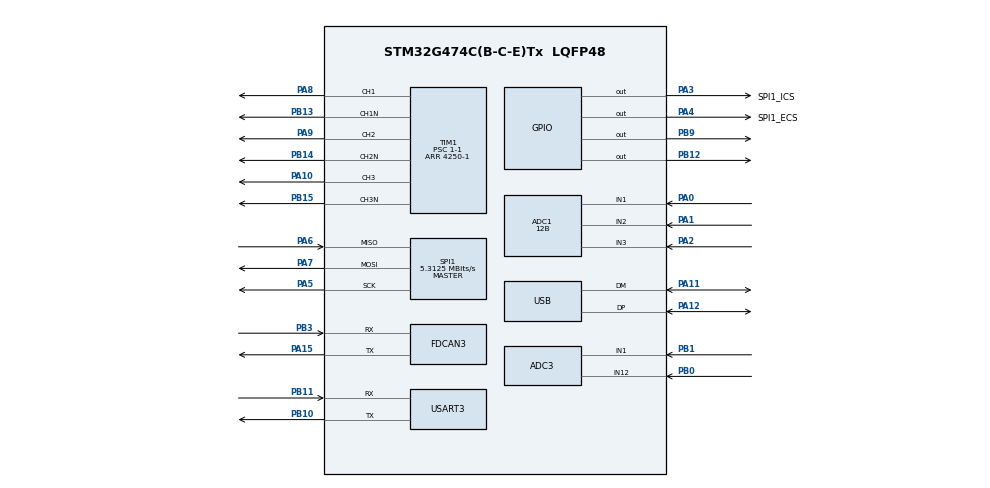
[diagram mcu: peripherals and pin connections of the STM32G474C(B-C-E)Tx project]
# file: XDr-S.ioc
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ADC1.Channel-0\#ChannelRegularConversion=ADC_CHANNEL_1
ADC1.Channel-1\#ChannelRegularConversion=ADC_CHANNEL_2
ADC1.Channel-2\#ChannelRegularConversion=ADC_CHANNEL_3
ADC1.DMAContinuousRequests=ENABLE
ADC1.ExternalTrigConv=ADC_EXTERNALTRIG_T1_TRGO
ADC1.ExternalTrigConvEdge=ADC_EXTERNALTRIGCONVEDGE_FALLING
ADC1.NbrOfConversion=3
ADC1.NbrOfConversionFlag=1
ADC1.OffsetNumber-0\#ChannelRegularConversion=ADC_OFFSET_NONE
ADC1.OffsetNumber-1\#ChannelRegularConversion=ADC_OFFSET_NONE
ADC1.OffsetNumber-2\#ChannelRegularConversion=ADC_OFFSET_NONE
ADC1.OversamplingMode=ENABLE
ADC1.Rank-0\#ChannelRegularConversion=1
ADC1.Rank-1\#ChannelRegularConversion=2
ADC1.Rank-2\#ChannelRegularConversion=3
ADC1.Ratio=ADC_OVERSAMPLING_RATIO_16
ADC1.Resolution=ADC_RESOLUTION_12B
ADC1.RightBitShift=ADC_RIGHTBITSHIFT_4
ADC1.SamplingTime-0\#ChannelRegularConversion=ADC_SAMPLETIME_2CYCLES_5
ADC1.SamplingTime-1\#ChannelRegularConversion=ADC_SAMPLETIME_2CYCLES_5
ADC1.SamplingTime-2\#ChannelRegularConversion=ADC_SAMPLETIME_2CYCLES_5
ADC1.master=1
ADC3.Channel-3\#ChannelRegularConversion=ADC_CHANNEL_12
ADC3.NbrOfConversionFlag=1
ADC3.OffsetNumber-3\#ChannelRegularConversion=ADC_OFFSET_NONE
ADC3.Rank-3\#ChannelRegularConversion=1
ADC3.SamplingTime-3\#ChannelRegularConversion=ADC_SAMPLETIME_2CYCLES_5
ADC3.master=1
Dma.ADC1.0.Direction=DMA_PERIPH_TO_MEMORY
Dma.ADC1.0.EventEnable=DISABLE
Dma.ADC1.0.Instance=DMA1_Channel1
Dma.ADC1.0.MemDataAlignment=DMA_MDATAALIGN_HALFWORD
Dma.ADC1.0.MemInc=DMA_MINC_ENABLE
Dma.ADC1.0.Mode=DMA_NORMAL
Dma.ADC1.0.PeriphDataAlignment=DMA_PDATAALIGN_HALFWORD
Dma.ADC1.0.PeriphInc=DMA_PINC_DISABLE
Dma.ADC1.0.Polarity=HAL_DMAMUX_REQ_GEN_RISING
Dma.ADC1.0.Priority=DMA_PRIORITY_HIGH
Dma.ADC1.0.RequestNumber=1
Dma.ADC1.0.SignalID=NONE
Dma.ADC1.0.SyncEnable=DISABLE
Dma.ADC1.0.SyncPolarity=HAL_DMAMUX_SYNC_NO_EVENT
Dma.ADC1.0.SyncRequestNumber=1
Dma.ADC1.0.SyncSignalID=NONE
Dma.Request0=ADC1
FDCAN3.AutoRetransmission=ENABLE
FDCAN3.CalculateBaudRateNominal=999999
FDCAN3.CalculateTimeBitNominal=1000
FDCAN3.CalculateTimeQuantumNominal=58.82352941176471
FDCAN3.DataSyncJumpWidth=3
FDCAN3.NominalPrescaler=10
FDCAN3.NominalTimeSeg1=12
FDCAN3.NominalTimeSeg2=4
FDCAN3.StdFiltersNbr=1
Mcu.Family=STM32G4
Mcu.Name=STM32G474C(B-C-E)Tx
Mcu.Package=LQFP48
NVIC.DMA1_Channel1_IRQn=true\:0\:1\:true\:false\:true\:false\:true\:true
NVIC.FDCAN3_IT0_IRQn=true\:0\:0\:false\:false\:true\:true\:true\:true
NVIC.PriorityGroup=NVIC_PRIORITYGROUP_2
NVIC.TIM1_UP_TIM16_IRQn=true\:0\:0\:false\:false\:true\:true\:true\:true
NVIC.USB_HP_IRQn=true\:0\:0\:false\:false\:true\:true\:true\:true
PA0.Mode=IN1-Single-Ended
PA0.Signal=ADC1_IN1
PA1.Mode=IN2-Single-Ended
PA1.Signal=ADC1_IN2
PA10.Signal=S_TIM1_CH3
PA11.Mode=Device
PA11.Signal=USB_DM
PA12.Mode=Device
PA12.Signal=USB_DP
PA13.Mode=Serial_Wire
PA13.Signal=SYS_JTMS-SWDIO
PA14.Mode=Serial_Wire
PA14.Signal=SYS_JTCK-SWCLK
PA15.Mode=FDCAN_Activate
PA15.Signal=FDCAN3_TX
PA2.Mode=IN3-Single-Ended
PA2.Signal=ADC1_IN3
PA3.GPIO_Label=SPI1_ICS
PA3.Signal=GPIO_Output
PA4.GPIO_Label=SPI1_ECS
PA4.Signal=GPIO_Output
PA5.Mode=Full_Duplex_Master
PA5.Signal=SPI1_SCK
PA6.Mode=Full_Duplex_Master
PA6.Signal=SPI1_MISO
PA7.Mode=Full_Duplex_Master
PA7.Signal=SPI1_MOSI
PA8.Signal=S_TIM1_CH1
PA9.Signal=S_TIM1_CH2
PB0.Mode=IN12-Single-Ended
PB0.Signal=ADC3_IN12
PB1.Mode=IN1-Single-Ended
PB1.Signal=ADC3_IN1
PB10.Mode=Asynchronous
PB10.Signal=USART3_TX
PB11.Mode=Asynchronous
PB11.Signal=USART3_RX
PB12.PinState=GPIO_PIN_SET
PB12.Signal=GPIO_Output
PB13.Mode=PWM Generation1 CH1 CH1N
PB13.Signal=TIM1_CH1N
PB14.Mode=PWM Generation2 CH2 CH2N
PB14.Signal=TIM1_CH2N
PB15.Mode=PWM Generation3 CH3 CH3N
PB15.Signal=TIM1_CH3N
PB3.Mode=FDCAN_Activate
PB3.Signal=FDCAN3_RX
PB9.Signal=GPIO_Output
PF0-OSC_IN.Mode=HSE-External-Oscillator
PF0-OSC_IN.Signal=RCC_OSC_IN
PF1-OSC_OUT.Mode=HSE-External-Oscillator
PF1-OSC_OUT.Signal=RCC_OSC_OUT
ProjectManager.HeapSize=0x800
ProjectManager.StackSize=0x1200
ProjectManager.TargetToolchain=CMake
RCC.ADC12Freq_Value=170000000
RCC.ADC345Freq_Value=170000000
RCC.AHBFreq_Value=170000000
RCC.APB1Freq_Value=170000000
RCC.APB1TimFreq_Value=170000000
RCC.APB2Freq_Value=170000000
RCC.APB2TimFreq_Value=170000000
RCC.CK48CLockSelection=RCC_USBCLKSOURCE_HSI48
RCC.CortexFreq_Value=170000000
RCC.EXTERNAL_CLOCK_VALUE=12288000
RCC.HCLKFreq_Value=170000000
RCC.HSE_VALUE=8000000
RCC.HSI48_VALUE=48000000
RCC.HSI_VALUE=16000000
RCC.LSE_VALUE=32768
RCC.PLLM=RCC_PLLM_DIV2
RCC.PLLN=85
RCC.PLLSourceVirtual=RCC_PLLSOURCE_HSE
RCC.SYSCLKFreq_VALUE=170000000
RCC.SYSCLKSource=RCC_SYSCLKSOURCE_PLLCLK
RCC.USBFreq_Value=48000000
RCC.VCOOutputFreq_Value=340000000
SH.S_TIM1_CH1.0=TIM1_CH1,PWM Generation1 CH1 CH1N
SH.S_TIM1_CH2.0=TIM1_CH2,PWM Generation2 CH2 CH2N
SH.S_TIM1_CH3.0=TIM1_CH3,PWM Generation3 CH3 CH3N
SPI1.BaudRatePrescaler=SPI_BAUDRATEPRESCALER_32
SPI1.CalculateBaudRate=5.3125 MBits/s
SPI1.Direction=SPI_DIRECTION_2LINES
SPI1.Mode=SPI_MODE_MASTER
SPI1.VirtualType=VM_MASTER
STMicroelectronics.X-CUBE-ALGOBUILD.1.5.0.LibraryCcDSPOoLibraryJjDSPOoLibrary=true
TIM1.AutoReloadPreload=TIM_AUTORELOAD_PRELOAD_ENABLE
TIM1.AutomaticOutput=TIM_AUTOMATICOUTPUT_ENABLE
TIM1.Channel-PWM\ Generation1\ CH1\ CH1N=TIM_CHANNEL_1
TIM1.Channel-PWM\ Generation2\ CH2\ CH2N=TIM_CHANNEL_2
TIM1.Channel-PWM\ Generation3\ CH3\ CH3N=TIM_CHANNEL_3
TIM1.Channel-PWM\ Generation4\ No\ Output=TIM_CHANNEL_4
TIM1.CounterMode=TIM_COUNTERMODE_CENTERALIGNED1
TIM1.DeadTime=17
TIM1.DeadTimePreload=ENABLE
TIM1.OffStateRunMode=TIM_OSSR_ENABLE
TIM1.PeriodNoDither=4250-1
TIM1.Prescaler=1-1
TIM1.PulseNoDither_4=4248
TIM1.TIM_MasterOutputTrigger=TIM_TRGO_OC4REF
TIM2.PeriodNoDither=5000-1
TIM2.Prescaler=170-1
TIM2.TIM_MasterOutputTrigger=TIM_TRGO_UPDATE
USART3.VirtualMode-Asynchronous=VM_ASYNC
VP_STMicroelectronics.X-CUBE-ALGOBUILD_VS_DSPOoLibraryJjLibrary_1.5.0_1.5.0.Mode=DSPOoLibraryJjLibrary
VP_SYS_VS_DBSignals.Mode=DisableDeadBatterySignals
VP_TIM1_VS_ClockSourceINT.Mode=Internal
VP_TIM1_VS_no_output4.Mode=PWM Generation4 No Output
VP_TIM2_VS_ClockSourceINT.Mode=Internal
board=custom

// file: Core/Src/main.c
/* USER CODE BEGIN Header */
/**
  ******************************************************************************
  * @file           : main.c
  * @brief          : Main program body
  ******************************************************************************
  * @attention
  *
  * Copyright (c) 2026 STMicroelectronics.
  * All rights reserved.
  *
  * This software is licensed under terms that can be found in the LICENSE file
  * in the root directory of this software component.
  * If no LICENSE file comes with this software, it is provided AS-IS.
  *
  ******************************************************************************
  */
/* USER CODE END Header */
#include "main.h"
#include "adc.h"
#include "dma.h"
#include "fdcan.h"
#include "spi.h"
#include "tim.h"
#include "usart.h"
#include "usb.h"
#include "gpio.h"

/* USER CODE BEGIN Includes */
#include "app_main.h"

/* USER CODE END Includes */

void SystemClock_Config(void);

int main(void)
{

  /* MCU Configuration--------------------------------------------------------*/

  /* Reset of all peripherals, Initializes the Flash interface and the Systick. */
  HAL_Init();

  /* Configure the system clock */
  SystemClock_Config();

  /* Initialize all configured peripherals */
  MX_GPIO_Init();
  MX_DMA_Init();
  MX_SPI1_Init();
  MX_TIM1_Init();
  MX_ADC1_Init();
  MX_TIM2_Init();
  MX_USB_PCD_Init();
  MX_ADC3_Init();
  MX_FDCAN3_Init();
  MX_USART3_UART_Init();
  /* USER CODE BEGIN 2 */
  if (!app_main_init())
    Error_Handler();
  app_main_start();
  /* USER CODE END 2 */

  /* Infinite loop */
  while (1)
  {

  }
}

void SystemClock_Config(void)
{
  LL_FLASH_SetLatency(LL_FLASH_LATENCY_4);
  while(LL_FLASH_GetLatency() != LL_FLASH_LATENCY_4)
  {
  }
  LL_PWR_EnableRange1BoostMode();
  LL_RCC_HSE_Enable();
   /* Wait till HSE is ready */
  while(LL_RCC_HSE_IsReady() != 1)
  {
  }

  LL_RCC_HSI48_Enable();
   /* Wait till HSI48 is ready */
  while(LL_RCC_HSI48_IsReady() != 1)
  {
  }

  LL_RCC_PLL_ConfigDomain_SYS(LL_RCC_PLLSOURCE_HSE, LL_RCC_PLLM_DIV_2, 85, LL_RCC_PLLR_DIV_2);
  LL_RCC_PLL_EnableDomain_SYS();
  LL_RCC_PLL_Enable();
   /* Wait till PLL is ready */
  while(LL_RCC_PLL_IsReady() != 1)
  {
  }

  LL_RCC_SetSysClkSource(LL_RCC_SYS_CLKSOURCE_PLL);
  LL_RCC_SetAHBPrescaler(LL_RCC_SYSCLK_DIV_2);
   /* Wait till System clock is ready */
  while(LL_RCC_GetSysClkSource() != LL_RCC_SYS_CLKSOURCE_STATUS_PLL)
  {
  }

  /* Insure 1us transition state at intermediate medium speed clock*/
  for (__IO uint32_t i = (170 >> 1); i !=0; i--);

  /* Set AHB prescaler*/
  LL_RCC_SetAHBPrescaler(LL_RCC_SYSCLK_DIV_1);
  LL_RCC_SetAPB1Prescaler(LL_RCC_APB1_DIV_1);
  LL_RCC_SetAPB2Prescaler(LL_RCC_APB2_DIV_1);
  LL_SetSystemCoreClock(170000000);

   /* Update the time base */
  if (HAL_InitTick (TICK_INT_PRIORITY) != HAL_OK)
  {
    Error_Handler();
  }
}

void Error_Handler(void)
{
  __disable_irq();
  while (1)
  {
  }
}
